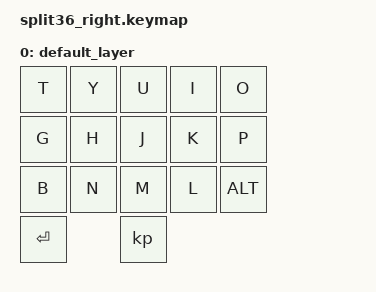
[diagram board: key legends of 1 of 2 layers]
keymap {
  compatible = "zmk,keymap";
  default_layer {
    bindings = <
      &kp T &kp Y &kp U &kp I &kp O
      &kp G &kp H &kp J &kp K &kp P
      &kp B &kp N &kp M &kp L &kp ALT
      &kp ENTER &kp ; &mo 1 
    >;
  };

  raise_layer {
    bindings = <
      &kp ! &kp @ &kp # &kp $ &kp %
      &kp ^ &kp & &kp * &bt BT_clear
      &kp F6 &kp F7 &kp F8 &kp F9 &kp F10
      &kp TRNS &kp TRNS &kp TRNS
    >;
  };
};
#comment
